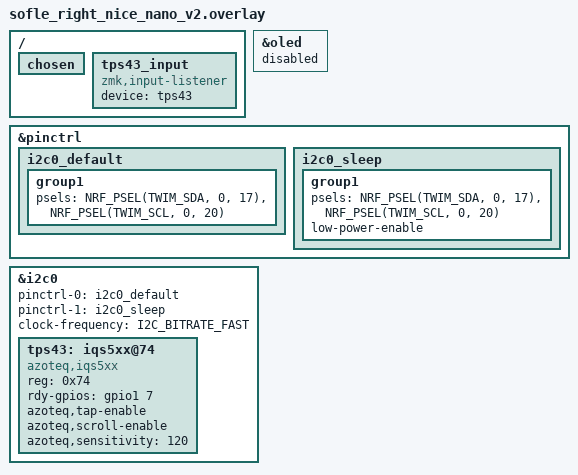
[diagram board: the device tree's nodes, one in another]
/*
 * sofle_right_nice_nano_v2.overlay
 * Lado DIREITO: desabilita OLED, adiciona TPS43 no I2C.
 */

#include <dt-bindings/zmk/input_transform.h>

/* Desabilita a OLED que o sofle_right.overlay original define */
&oled {
    status = "disabled";
};

/* Remove o display do chosen */
/ {
    chosen {
        /delete-property/ zephyr,display;
    };
};

/* Redefine pinctrl I2C nos pinos da OLED (P0.17=SDA, P0.20=SCL) */
&pinctrl {
    i2c0_default: i2c0_default {
        group1 {
            psels = <NRF_PSEL(TWIM_SDA, 0, 17)>,
                    <NRF_PSEL(TWIM_SCL, 0, 20)>;
        };
    };
    i2c0_sleep: i2c0_sleep {
        group1 {
            psels = <NRF_PSEL(TWIM_SDA, 0, 17)>,
                    <NRF_PSEL(TWIM_SCL, 0, 20)>;
            low-power-enable;
        };
    };
};

/* Adiciona TPS43 no mesmo barramento I2C */
&i2c0 {
    status = "okay";
    pinctrl-0 = <&i2c0_default>;
    pinctrl-1 = <&i2c0_sleep>;
    pinctrl-names = "default", "sleep";
    clock-frequency = <I2C_BITRATE_FAST>;

    tps43: iqs5xx@74 {
        status = "okay";
        compatible = "azoteq,iqs5xx";
        reg = <0x74>;
        rdy-gpios = <&gpio1 7 GPIO_ACTIVE_HIGH>;
        azoteq,tap-enable;
        azoteq,scroll-enable;
        azoteq,sensitivity = <120>;
    };
};

/ {
    tps43_input: tps43_input {
        compatible = "zmk,input-listener";
        device = <&tps43>;
    };
};
